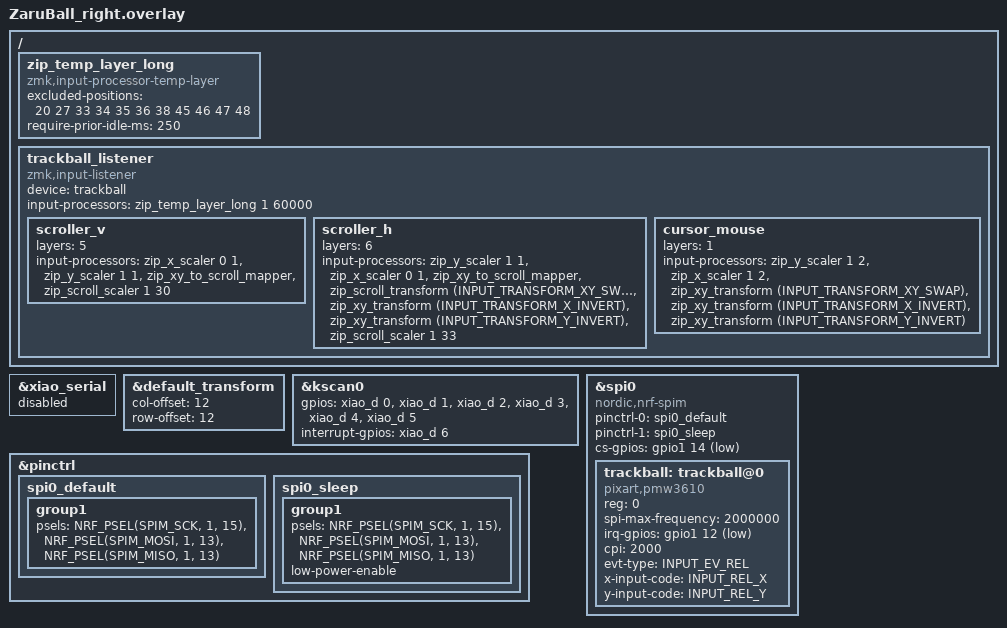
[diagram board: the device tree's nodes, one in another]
#include "ZaruBall.dtsi"
#include <input/processors.dtsi>
#include <dt-bindings/zmk/input_transform.h>
#include <zephyr/dt-bindings/input/input-event-codes.h>

&xiao_serial { status = "disabled"; };

&default_transform {
    col-offset = <12>;
    row-offset = <12>;
};

&kscan0 {
    gpios = <&xiao_d 0 GPIO_ACTIVE_HIGH>, /* M1 */
            <&xiao_d 1 GPIO_ACTIVE_HIGH>, /* M2 */
            <&xiao_d 2 GPIO_ACTIVE_HIGH>, /* M3 */
            <&xiao_d 3 GPIO_ACTIVE_HIGH>, /* M4 */
            <&xiao_d 4 GPIO_ACTIVE_HIGH>, /* M5 */
            <&xiao_d 5 GPIO_ACTIVE_HIGH>; /* M6 */

    interrupt-gpios = <&xiao_d 6 (GPIO_ACTIVE_HIGH | GPIO_PULL_DOWN)>; /* IGPIO */
};

&pinctrl {
    spi0_default: spi0_default {
        group1 {
            psels = <NRF_PSEL(SPIM_SCK, 1, 15)>,  /* SCLK */
                    <NRF_PSEL(SPIM_MOSI, 1, 13)>, /* SDIO */
                    <NRF_PSEL(SPIM_MISO, 1, 13)>; /* SDIO */
        };
    };

    spi0_sleep: spi0_sleep {
        group1 {
            psels = <NRF_PSEL(SPIM_SCK, 1, 15)>,
                    <NRF_PSEL(SPIM_MOSI, 1, 13)>,
                    <NRF_PSEL(SPIM_MISO, 1, 13)>;
            low-power-enable;
        };
    };
};

&spi0 {
    status = "okay";
    compatible = "nordic,nrf-spim";
    pinctrl-0 = <&spi0_default>;
    pinctrl-1 = <&spi0_sleep>;
    pinctrl-names = "default", "sleep";
    cs-gpios = <&gpio1 14 GPIO_ACTIVE_LOW>; /* CS */

    trackball: trackball@0 {
        status = "okay";
        compatible = "pixart,pmw3610";
        reg = <0>;
        spi-max-frequency = <2000000>;
        irq-gpios = <&gpio1 12 (GPIO_ACTIVE_LOW | GPIO_PULL_UP)>; /* MOTION */

        cpi = <2000>;

        evt-type = <INPUT_EV_REL>;
        x-input-code = <INPUT_REL_X>;
        y-input-code = <INPUT_REL_Y>;
    };
};

/* ---- Auto Mouse Layer ---- */
 / {
    zip_temp_layer_long: zip_temp_layer_long {
        compatible = "zmk,input-processor-temp-layer";
        #input-processor-cells = <2>;

        excluded-positions = <20 27 33 34 35 36 38 45 46 47 48>;
        require-prior-idle-ms = <250>;
    };
};

 / {
  trackball_listener {
    compatible = "zmk,input-listener";
    device = <&trackball>;

    /* 動いたら layer1 を 60s 付与（現状維持） */
    input-processors = <
        &zip_temp_layer_long  1 60000
    >;

    /* =======================
     * スクロールを最優先（完璧になった状態を維持）
     * ======================= */

    scroller_v {
        layers = <5>;
        input-processors = <
            &zip_x_scaler 0 1
            &zip_y_scaler 1 1
            &zip_xy_to_scroll_mapper
            &zip_scroll_scaler 1 30
        >;
    };

    scroller_h {
        layers = <6>;
        input-processors = <
            &zip_y_scaler 1 1
            &zip_x_scaler 0 1
            &zip_xy_to_scroll_mapper
            &zip_scroll_transform (INPUT_TRANSFORM_XY_SWAP)
            &zip_xy_transform (INPUT_TRANSFORM_X_INVERT)
            &zip_xy_transform (INPUT_TRANSFORM_Y_INVERT)
            &zip_scroll_scaler 1 33
        >;
    };

    /* =======================
     * カーソル（layer1）だけ XY を補正
     * ※必ず最後に置く
     * ======================= */
    cursor_mouse {
        layers = <1>;
        input-processors = <
            &zip_y_scaler 1 2
            &zip_x_scaler 1 2
            &zip_xy_transform (INPUT_TRANSFORM_XY_SWAP)
            &zip_xy_transform (INPUT_TRANSFORM_X_INVERT)
            &zip_xy_transform (INPUT_TRANSFORM_Y_INVERT)
        >;
    };
  };
};
